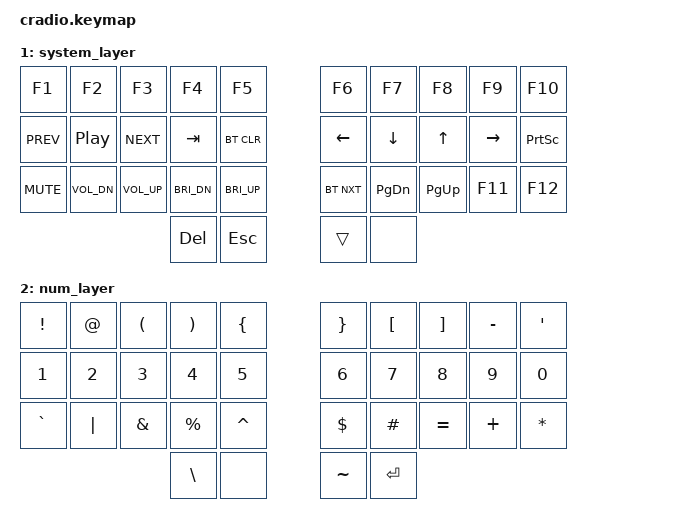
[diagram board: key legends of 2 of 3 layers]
// Copyright (c) 2022 The ZMK Contributors
// SPDX-License-Identifier: MIT

#include <behaviors.dtsi>
#include <dt-bindings/zmk/keys.h>
#include <dt-bindings/zmk/bt.h>

// Home row mods macro
#define HRML(k1,k2,k3,k4) &ht LSHFT k1  &ht LCTRL k2  &ht LGUI  k3  &ht LALT  k4
#define HRMR(k1,k2,k3,k4) &ht LALT  k1  &ht RGUI  k2  &ht RCTRL k3  &ht RSHFT k4

/ {
    behaviors {
        ht: hold_tap {
            compatible = "zmk,behavior-hold-tap";
            #binding-cells = <2>;
            flavor = "tap-preferred";
            tapping-term-ms = <200>;
            quick-tap-ms = <150>;
            require-prior-idle-ms = <100>;
            bindings = <&kp>, <&kp>;
        };
    };

    keymap {
        compatible = "zmk,keymap";
        default_layer {
            bindings = <
        //╭──────────┬──────────┬──────────┬──────────┬──────────╮   ╭──────────┬──────────┬──────────┬──────────┬──────────╮
        //│  Q       │  W       │  E       │  R       │  T       │   │  Y       │  U       │  I       │  O       │  P       │
            &kp Q      &kp W      &kp E      &kp R      &kp T          &kp Y      &kp U      &kp I      &kp O      &kp P
        //├──────────┼──────────┼──────────┼──────────┼──────────┤   ├──────────┼──────────┼──────────┼──────────┼──────────┤
        //│  A       │  S       │  D       │  F       │  G       │   │  H       │  J       │  K       │  L       │ ' "      │
            HRML(A,        S,         D,         F)     &kp G          &kp H      HRMR(J,        K,         L,        SEMI)
        //├──────────┼──────────┼──────────┼──────────┼──────────┤   ├──────────┼──────────┼──────────┼──────────┼──────────┤
        //│  Z       │  X       │  C       │  V       │  B       │   │  N       │  M       │ , <      │ . >      │ / ?      │
            &kp Z      &kp X      &kp C      &kp V      &kp B          &kp N      &kp M      &kp COMMA  &kp DOT    &kp FSLH
        //╰──────────┴──────────┴──────────┼──────────┼──────────┤   ├──────────┼──────────┼──────────┴──────────┴──────────╯
                                             &kp BSPC   &mo 2          &lt 1 RALT &kp SPACE
        //                                 ╰──────────┴──────────╯   ╰──────────┴──────────╯
            >;
        };

        system_layer {
            bindings = <
        //╭──────────┬──────────┬──────────┬──────────┬──────────╮   ╭──────────┬──────────┬──────────┬──────────┬──────────╮
        //│  F1      │  F2      │  F3      │  F4      │  F5      │   │  F6      │  F7      │  F8      │  F9      │  F10     │
            &kp F1     &kp F2     &kp F3     &kp F4     &kp F5         &kp F6     &kp F7     &kp F8     &kp F9     &kp F10
        //├──────────┼──────────┼──────────┼──────────┼──────────┤   ├──────────┼──────────┼──────────┼──────────┼──────────┤
        //│ PREV     │ PLAY     │ NEXT     │ TAB      │ BT CLEAR │   │ LEFT     │ DOWN     │ UP       │ RIGHT    │  PrSc    │
            &kp C_PREV &kp C_PP   &kp C_NEXT &kp TAB    &bt BT_CLR     &kp LEFT   &kp DOWN   &kp UP     &kp RIGHT  &kp PSCRN
        //├──────────┼──────────┼──────────┼──────────┼──────────┤   ├──────────┼──────────┼──────────┼──────────┼──────────┤
        //│ MUTE     │  VOL-    │  VOL+    │ BRI -    │ BRI +    │   │ BT NEXT  │ PGDN     │ PGUP     │ F11      │ F12      │
           &kp C_MUTE &kp C_VOL_DN &kp C_VOL_UP &kp C_BRI_DN &kp C_BRI_UP &bt BT_NXT &kp PG_DN &kp PG_UP &kp F11 &kp F12
        //╰──────────┴──────────┴──────────┼──────────┼──────────┤   ├──────────┼──────────┼──────────┴──────────┴──────────╯
                                             &kp DEL    &kp ESC        &trans     &none
        //                                 ╰──────────┴──────────╯   ╰──────────┴──────────╯
            >;
        };

        num_layer {
            bindings = <
        //╭──────────┬──────────┬──────────┬──────────┬──────────╮   ╭──────────┬──────────┬──────────┬──────────┬──────────╮
        //│ !        │  @       │  (       │  )       │ {        │   │  }       │  [       │  ]       │  -       │  '       │
            &kp EXCL   &kp AT     &kp LPAR   &kp RPAR   &kp LBRC       &kp RBRC   &kp LBKT   &kp RBKT   &kp MINUS  &kp APOS
        //├──────────┼──────────┼──────────┼──────────┼──────────┤   ├──────────┼──────────┼──────────┼──────────┼──────────┤
        //│  1       │  2       │  3       │  4       │  5       │   │  6       │  7       │  8       │  9       │  0       │
            &kp N1     &kp N2     &kp N3     &kp N4     &kp N5         &kp N6     &kp N7     &kp N8     &kp N9     &kp N0
        //├──────────┼──────────┼──────────┼──────────┼──────────┤   ├──────────┼──────────┼──────────┼──────────┼──────────┤
        //│  `       │  |       │  &       │  %       │  ^       │   │  $       │  #       │  =       │  +       │  *       │
            &kp GRAVE  &kp PIPE   &kp AMPS   &kp PRCNT  &kp CARET      &kp DLLR   &kp HASH   &kp EQUAL  &kp PLUS   &kp STAR
        //╰──────────┴──────────┴──────────┼──────────┼──────────┤   ├──────────┼──────────┼──────────┴──────────┴──────────╯
                                             &kp BSLH   &none          &kp TILDE  &kp RET
        //                                 ╰──────────┴──────────╯   ╰──────────┴──────────╯
            >;
        };
    };
};
